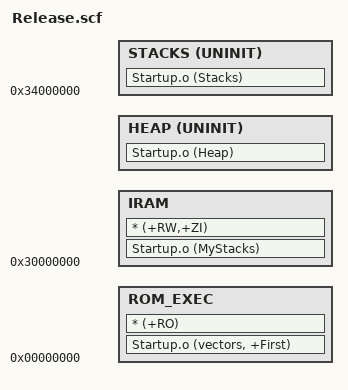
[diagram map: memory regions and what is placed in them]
;/****************************************Copyright (c)**************************************************
;**                               Guangzhou ZHIYUAN electronics Co.,LTD.
;**                                     
;**                                 http://www.zyinside.com
;**
;**--------------File Info-------------------------------------------------------------------------------
;** File Name:          Release.scf
;** Last modified Date: 2006-01-06 
;** Last Version:       v2.0
;** Descriptions:       Scatter File
;**
;**------------------------------------------------------------------------------------------------------
;** Created By:         Chenmingji
;** Created date:       2004-09-17
;** Version:            v1.0
;** Descriptions:       创建
;**
;**------------------------------------------------------------------------------------------------------
;** Modified by:        甘达
;** Modified date:      2006-01-06 
;** Version:            v2.0
;** Descriptions:       修改用于S3C2410
;**
;**------------------------------------------------------------------------------------------------------
;** Modified by:      
;** Modified date:     
;** Version:           
;** Descriptions:      
;**
;********************************************************************************************************/
ROM_LOAD 0x00000000                     ;// 加载区起始地址(位于SDRAM)
{
    ROM_EXEC 0x00000000                 ;// 执行区起点
    {
        Startup.o (vectors, +First)     ;// 放置启动代码定义的向量部分
        * (+RO)
    }
    
    IRAM 0x30000000                     ;// 变量区起始地址(位于SDRAM)
    {                                   
        Startup.o (MyStacks)            ;// 放置启动代码定义的MyStacks部分    
        * (+RW,+ZI)                     ;// 放置其他变量并且清零
    }

    HEAP +0 UNINIT                      ;// 系统堆区起始地址(位于SDRAM)
    {
        Startup.o (Heap)                ;// 放置启动代码定义的Heap部分 
    }

    STACKS 0x34000000 UNINIT            ;// 系统栈区终止地址(位于SDRAM)
    {                                   
        Startup.o (Stacks)              ;// 放置启动代码定义的Stacks部分
    }
}

;/********************************************************************************************************
;**                            End Of File
;********************************************************************************************************/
